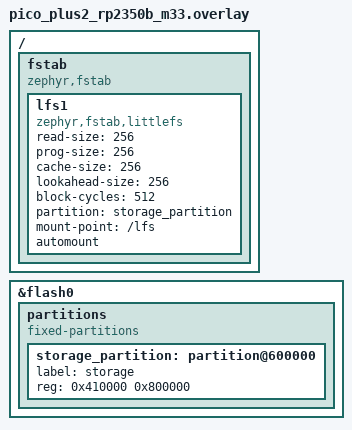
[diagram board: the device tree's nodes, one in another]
&flash0 {
	partitions {
		compatible = "fixed-partitions";
		#address-cells = <1>;
		#size-cells = <1>;

	  	storage_partition: partition@600000 {
	  		label = "storage";
	        reg = <0x410000 0x800000>;
	  	};
	};
};

/ {
	fstab {
		compatible = "zephyr,fstab";
		lfs1: lfs1 {
			compatible = "zephyr,fstab,littlefs";
			read-size = <256>;
			prog-size = <256>;
			cache-size = <256>;
			lookahead-size = <256>;
			block-cycles = <512>;
			partition = <&storage_partition>;
			mount-point = "/lfs";
			automount;
		};
	};
};
